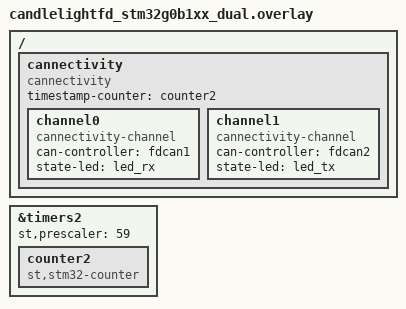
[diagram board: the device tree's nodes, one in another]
/*
 * Copyright (c) 2024-2025 Henrik Brix Andersen <henrik@brixandersen.dk>
 *
 * SPDX-License-Identifier: Apache-2.0
 */

#include <zephyr/dt-bindings/gpio/gpio.h>
#include "../app.overlay"

/ {
	cannectivity: cannectivity {
		compatible = "cannectivity";
		timestamp-counter = <&counter2>;

		channel0 {
			compatible = "cannectivity-channel";
			can-controller = <&fdcan1>;
			/* Use RX LED for channel 0 state + activity */
			state-led = <&led_rx>;
		};

		channel1 {
			compatible = "cannectivity-channel";
			can-controller = <&fdcan2>;
			/* Use TX LED for channel 0 state + activity */
			state-led = <&led_tx>;
		};
	};
};

&timers2 {
	status = "okay";
	st,prescaler = <59>;

	counter2: counter2 {
		compatible = "st,stm32-counter";
		status = "okay";
	};
};
